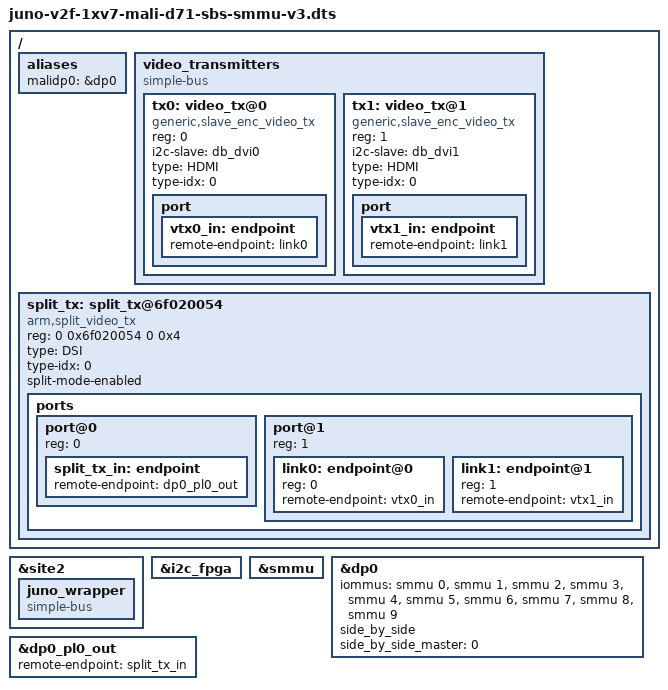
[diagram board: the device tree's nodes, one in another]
/*
 * ARM Juno development platform with single Virtex 7 logic tile
 * and HDMI daughterboard.
 * Configured for a bitfile containing a Mali-Cetus.
 */

#include "juno-r0.dts"
#include "juno-fpga.dtsi"

/ {
	aliases {
		malidp0 = &dp0;
	};

	video_transmitters {
		compatible = "simple-bus";
		#address-cells = <1>;
		#size-cells = <0>;

		tx0: video_tx@0 {
			compatible = "generic,slave_enc_video_tx";
			reg = <0>;
			i2c-slave = <&db_dvi0>;
			type = "HDMI";
			type-idx = <0>;
			status = "okay";
			port {
				vtx0_in: endpoint {
					remote-endpoint = <&link0>;
				};
			};
		};

		tx1: video_tx@1 {
			compatible = "generic,slave_enc_video_tx";
			reg = <1>;
			i2c-slave = <&db_dvi1>;
			type = "HDMI";
			type-idx = <0>;
			status = "okay";
			port {
				vtx1_in: endpoint {
					remote-endpoint = <&link1>;
				};
			};
		};
	};

	split_tx: split_tx@6f020054 {
		compatible = "arm,split_video_tx";
		reg = <0 0x6f020054 0 0x4>;
		type = "DSI";
		type-idx = <0>;
		split-mode-enabled;
		ports {
			#address-cells = <1>;
			#size-cells = <0>;

			/* Input from the DP. Contains both links */
			port@0 {
				reg = <0>;
				split_tx_in: endpoint {
					remote-endpoint = <&dp0_pl0_out>;
				};
			};

			port@1 {
				reg = <1>;
				#address-cells = <1>;
				#size-cells = <0>;
				link0: endpoint@0 {
					reg = <0>;
					remote-endpoint = <&vtx0_in>;
				};
				link1: endpoint@1 {
					reg = <1>;
					remote-endpoint = <&vtx1_in>;
				};
			};
		};
	};
};

&site2 {
	juno_wrapper {
		compatible = "simple-bus";
		#address-cells = <1>;
		#size-cells = <1>;
		/*
		 * The mapping on Juno is rather complicated.
		 * The lowest slaves: 0-0x0009ffff are mapped to 0x6f100000 (physical)
		 * The "mid" slaves:  0x00200000-0x00ffffff are mapped to 0x6f200000 (physical)
		 * The "high" slaves: 0x0c000000-0x0c09ffff are mapped to 0x6f000000 (physical)
		 */
		ranges = <0          0x0f100000 0x0a0000>,
			 <0x00200000 0x0f200000 0xe00000>,
			 <0x0c000000 0x0f000000 0x0a0000>;

		/include/ "v2f-1xv7-malidp-framework.dtsi"
		/include/ "v2f-1xv7-malidp-d71.dtsi"
	};
};

&i2c_fpga {
	status = "okay";
	/include/ "v2c-hdmi.dtsi"
};

&smmu {
	status = "okay";
	#iommu-cells = <1>;
};

/* Configure DP0 with daughterboard transmitters */
&dp0 {
	iommus = <&smmu 0>, <&smmu 1>, <&smmu 2>, <&smmu 3>,
		 <&smmu 4>, <&smmu 5>, <&smmu 6>, <&smmu 7>,
		 <&smmu 8>, <&smmu 9>;
	status = "okay";
	side_by_side;
	side_by_side_master = <0>;
};

&dp0_pl0_out {
	remote-endpoint = <&split_tx_in>;
};
